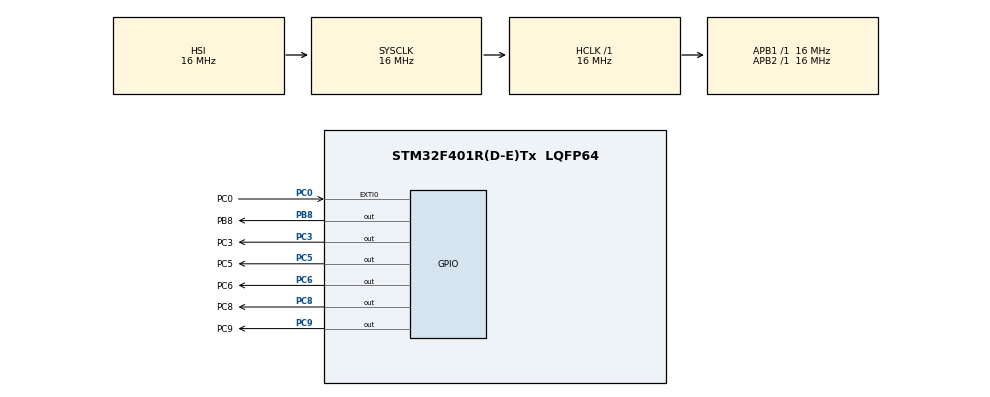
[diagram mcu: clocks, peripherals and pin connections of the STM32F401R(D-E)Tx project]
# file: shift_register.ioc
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Mcu.Family=STM32F4
Mcu.Name=STM32F401R(D-E)Tx
Mcu.Package=LQFP64
NVIC.EXTI0_IRQn=true\:0\:0\:false\:false\:true\:true\:true\:true
NVIC.PVD_IRQn=true\:0\:0\:false\:false\:true\:true\:true\:true
NVIC.PriorityGroup=NVIC_PRIORITYGROUP_4
PB8.GPIO_Label=PB8
PB8.Signal=GPIO_Output
PC0.GPIO_Label=PC0
PC0.Signal=GPXTI0
PC3.GPIO_Label=PC3
PC3.Signal=GPIO_Output
PC5.GPIO_Label=PC5
PC5.Signal=GPIO_Output
PC6.GPIO_Label=PC6
PC6.Signal=GPIO_Output
PC8.GPIO_Label=PC8
PC8.Signal=GPIO_Output
PC9.GPIO_Label=PC9
PC9.Signal=GPIO_Output
ProjectManager.HeapSize=0x200
ProjectManager.StackSize=0x400
ProjectManager.TargetToolchain=STM32CubeIDE
RCC.AHBFreq_Value=16000000
RCC.APB1Freq_Value=16000000
RCC.APB2Freq_Value=16000000
RCC.CortexFreq_Value=16000000
RCC.HSE_VALUE=25000000
RCC.HSI_VALUE=16000000
RCC.LSE_VALUE=32768
RCC.SYSCLKFreq_VALUE=16000000
RCC.VCOOutputFreq_Value=192000000
board=custom

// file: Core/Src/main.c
/* USER CODE BEGIN Header */
/**
  ******************************************************************************
  * @file           : main.c
  * @brief          : Main program body
  ******************************************************************************
  * @attention
  *
  * Copyright (c) 2025 STMicroelectronics.
  * All rights reserved.
  *
  * This software is licensed under terms that can be found in the LICENSE file
  * in the root directory of this software component.
  * If no LICENSE file comes with this software, it is provided AS-IS.
  *
  ******************************************************************************
  */
/* USER CODE END Header */
#include "main.h"

void SystemClock_Config(void);
static void MX_GPIO_Init(void);

int main(void)
{

  /* MCU Configuration--------------------------------------------------------*/

  /* Reset of all peripherals, Initializes the Flash interface and the Systick. */
  HAL_Init();

  /* Configure the system clock */
  SystemClock_Config();

  /* Initialize all configured peripherals */
  MX_GPIO_Init();

  /* Infinite loop */
  /* USER CODE BEGIN WHILE */

  init_74hc(PC5_GPIO_Port, PC8_Pin, PC9_Pin, PC6_Pin, PC5_Pin,PC3_Pin);

  en_clear_clock();
  en_enable_output();

  while (1)
  {
    /* USER CODE END WHILE */

  }
}

void HAL_GPIO_EXTI_Callback(uint16_t gpio_pin)
{

	uint8_t data = 0b00000011;

	if(gpio_pin == PC0_Pin)
	{
		send_data(data);
	}

}

void SystemClock_Config(void)
{
  RCC_OscInitTypeDef RCC_OscInitStruct = {0};
  RCC_ClkInitTypeDef RCC_ClkInitStruct = {0};

  /** Configure the main internal regulator output voltage
  */
  __HAL_RCC_PWR_CLK_ENABLE();
  __HAL_PWR_VOLTAGESCALING_CONFIG(PWR_REGULATOR_VOLTAGE_SCALE2);

  /** Initializes the RCC Oscillators according to the specified parameters
  * in the RCC_OscInitTypeDef structure.
  */
  RCC_OscInitStruct.OscillatorType = RCC_OSCILLATORTYPE_HSI;
  RCC_OscInitStruct.HSIState = RCC_HSI_ON;
  RCC_OscInitStruct.HSICalibrationValue = RCC_HSICALIBRATION_DEFAULT;
  RCC_OscInitStruct.PLL.PLLState = RCC_PLL_NONE;
  if (HAL_RCC_OscConfig(&RCC_OscInitStruct) != HAL_OK)
  {
    Error_Handler();
  }

  /** Initializes the CPU, AHB and APB buses clocks
  */
  RCC_ClkInitStruct.ClockType = RCC_CLOCKTYPE_HCLK|RCC_CLOCKTYPE_SYSCLK
                              |RCC_CLOCKTYPE_PCLK1|RCC_CLOCKTYPE_PCLK2;
  RCC_ClkInitStruct.SYSCLKSource = RCC_SYSCLKSOURCE_HSI;
  RCC_ClkInitStruct.AHBCLKDivider = RCC_SYSCLK_DIV1;
  RCC_ClkInitStruct.APB1CLKDivider = RCC_HCLK_DIV1;
  RCC_ClkInitStruct.APB2CLKDivider = RCC_HCLK_DIV1;

  if (HAL_RCC_ClockConfig(&RCC_ClkInitStruct, FLASH_LATENCY_0) != HAL_OK)
  {
    Error_Handler();
  }
}

static void MX_GPIO_Init(void)
{
  GPIO_InitTypeDef GPIO_InitStruct = {0};

  /* GPIO Ports Clock Enable */
  __HAL_RCC_GPIOC_CLK_ENABLE();
  __HAL_RCC_GPIOB_CLK_ENABLE();

  /*Configure GPIO pin Output Level */
  HAL_GPIO_WritePin(GPIOC, PC3_Pin|PC5_Pin|PC6_Pin|PC8_Pin
                          |PC9_Pin, GPIO_PIN_RESET);

  /*Configure GPIO pin Output Level */
  HAL_GPIO_WritePin(PB8_GPIO_Port, PB8_Pin, GPIO_PIN_RESET);

  /*Configure GPIO pin : PC0_Pin */
  GPIO_InitStruct.Pin = PC0_Pin;
  GPIO_InitStruct.Mode = GPIO_MODE_IT_RISING;
  GPIO_InitStruct.Pull = GPIO_NOPULL;
  HAL_GPIO_Init(PC0_GPIO_Port, &GPIO_InitStruct);

  /*Configure GPIO pins : PC3_Pin PC5_Pin PC6_Pin PC8_Pin
                           PC9_Pin */
  GPIO_InitStruct.Pin = PC3_Pin|PC5_Pin|PC6_Pin|PC8_Pin
                          |PC9_Pin;
  GPIO_InitStruct.Mode = GPIO_MODE_OUTPUT_PP;
  GPIO_InitStruct.Pull = GPIO_NOPULL;
  GPIO_InitStruct.Speed = GPIO_SPEED_FREQ_LOW;
  HAL_GPIO_Init(GPIOC, &GPIO_InitStruct);

  /*Configure GPIO pin : PB8_Pin */
  GPIO_InitStruct.Pin = PB8_Pin;
  GPIO_InitStruct.Mode = GPIO_MODE_OUTPUT_PP;
  GPIO_InitStruct.Pull = GPIO_NOPULL;
  GPIO_InitStruct.Speed = GPIO_SPEED_FREQ_LOW;
  HAL_GPIO_Init(PB8_GPIO_Port, &GPIO_InitStruct);

  /* EXTI interrupt init*/
  HAL_NVIC_SetPriority(EXTI0_IRQn, 0, 0);
  HAL_NVIC_EnableIRQ(EXTI0_IRQn);

}

void Error_Handler(void)
{
  __disable_irq();
  while (1)
  {
  }
}
